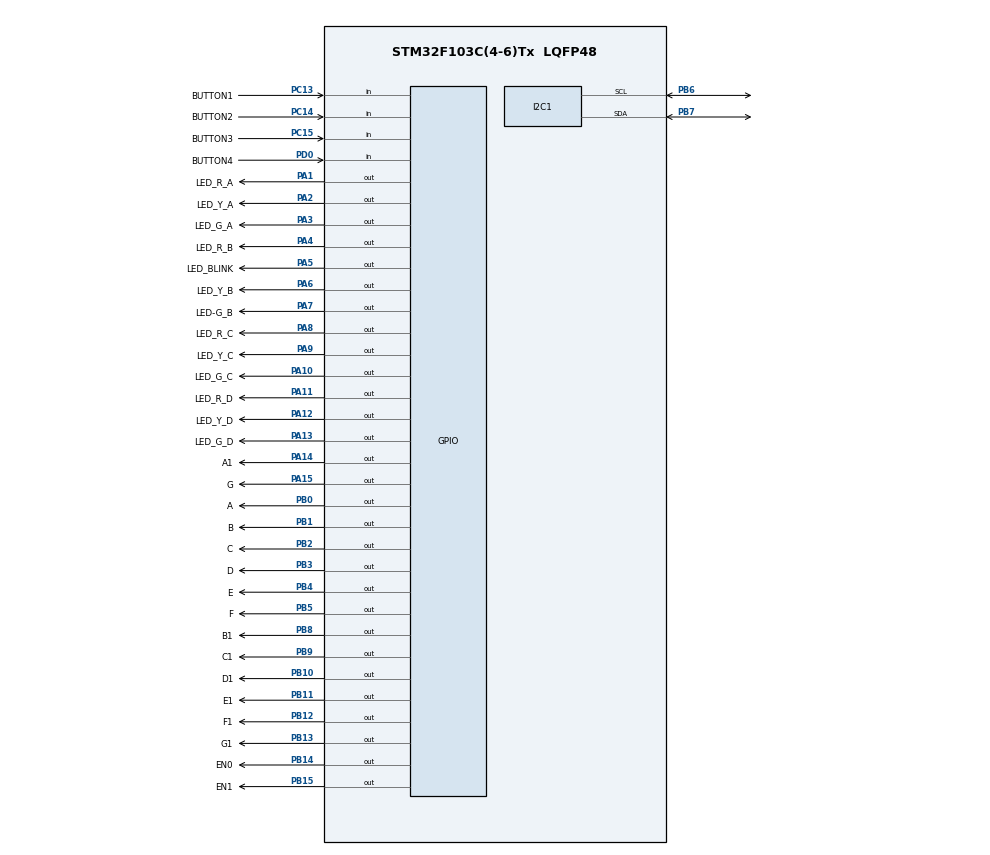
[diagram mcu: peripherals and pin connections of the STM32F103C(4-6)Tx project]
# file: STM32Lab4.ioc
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Mcu.Family=STM32F1
Mcu.Name=STM32F103C(4-6)Tx
Mcu.Package=LQFP48
NVIC.PriorityGroup=NVIC_PRIORITYGROUP_4
NVIC.TIM2_IRQn=true\:0\:0\:false\:false\:true\:true\:true\:true
PA1.GPIO_Label=LED_R_A
PA1.Signal=GPIO_Output
PA10.GPIO_Label=LED_G_C
PA10.Signal=GPIO_Output
PA11.GPIO_Label=LED_R_D
PA11.Signal=GPIO_Output
PA12.GPIO_Label=LED_Y_D
PA12.Signal=GPIO_Output
PA13.GPIO_Label=LED_G_D
PA13.Signal=GPIO_Output
PA14.GPIO_Label=A1
PA14.Signal=GPIO_Output
PA15.GPIO_Label=G
PA15.Signal=GPIO_Output
PA2.GPIO_Label=LED_Y_A
PA2.Signal=GPIO_Output
PA3.GPIO_Label=LED_G_A
PA3.Signal=GPIO_Output
PA4.GPIO_Label=LED_R_B
PA4.Signal=GPIO_Output
PA5.GPIO_Label=LED_BLINK
PA5.Signal=GPIO_Output
PA6.GPIO_Label=LED_Y_B
PA6.Signal=GPIO_Output
PA7.GPIO_Label=LED-G_B
PA7.Signal=GPIO_Output
PA8.GPIO_Label=LED_R_C
PA8.Signal=GPIO_Output
PA9.GPIO_Label=LED_Y_C
PA9.Signal=GPIO_Output
PB0.GPIO_Label=A
PB0.Signal=GPIO_Output
PB1.GPIO_Label=B
PB1.Signal=GPIO_Output
PB10.GPIO_Label=D1
PB10.Signal=GPIO_Output
PB11.GPIO_Label=E1
PB11.Signal=GPIO_Output
PB12.GPIO_Label=F1
PB12.Signal=GPIO_Output
PB13.GPIO_Label=G1
PB13.Signal=GPIO_Output
PB14.GPIO_Label=EN0
PB14.Signal=GPIO_Output
PB15.GPIO_Label=EN1
PB15.Signal=GPIO_Output
PB2.GPIO_Label=C
PB2.Signal=GPIO_Output
PB3.GPIO_Label=D
PB3.Signal=GPIO_Output
PB4.GPIO_Label=E
PB4.Signal=GPIO_Output
PB5.GPIO_Label=F
PB5.Signal=GPIO_Output
PB6.Mode=I2C
PB6.Signal=I2C1_SCL
PB7.Mode=I2C
PB7.Signal=I2C1_SDA
PB8.GPIO_Label=B1
PB8.Signal=GPIO_Output
PB9.GPIO_Label=C1
PB9.Signal=GPIO_Output
PC13-TAMPER-RTC.GPIO_Label=BUTTON1
PC13-TAMPER-RTC.GPIO_PuPd=GPIO_PULLUP
PC13-TAMPER-RTC.Signal=GPIO_Input
PC14-OSC32_IN.GPIO_Label=BUTTON2
PC14-OSC32_IN.GPIO_PuPd=GPIO_PULLUP
PC14-OSC32_IN.Signal=GPIO_Input
PC15-OSC32_OUT.GPIO_Label=BUTTON3
PC15-OSC32_OUT.GPIO_PuPd=GPIO_PULLUP
PC15-OSC32_OUT.Signal=GPIO_Input
PD0-OSC_IN.GPIO_Label=BUTTON4
PD0-OSC_IN.Signal=GPIO_Input
ProjectManager.HeapSize=0x200
ProjectManager.StackSize=0x400
ProjectManager.TargetToolchain=STM32CubeIDE
RCC.APB1Freq_Value=8000000
RCC.APB2Freq_Value=8000000
TIM2.Period=9
TIM2.Prescaler=7999
VP_SYS_VS_ND.Mode=No_Debug
VP_TIM2_VS_ClockSourceINT.Mode=Internal
board=custom

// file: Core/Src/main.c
/* USER CODE BEGIN Header */
/**
  ******************************************************************************
  * @file           : main.c
  * @brief          : Main program body
  ******************************************************************************
  * @attention
  *
  * <h2><center>&copy; Copyright (c) 2025 STMicroelectronics.
  * All rights reserved.</center></h2>
  *
  * This software component is licensed by ST under BSD 3-Clause license,
  * the "License"; You may not use this file except in compliance with the
  * License. You may obtain a copy of the License at:
  *                        opensource.org/licenses/BSD-3-Clause
  *
  ******************************************************************************
  */
/* USER CODE END Header */
#include "main.h"

/* USER CODE BEGIN Includes */
#include "Task.h"

/* USER CODE END Includes */

I2C_HandleTypeDef hi2c1;

TIM_HandleTypeDef htim2;

void SystemClock_Config(void);
static void MX_GPIO_Init(void);
static void MX_TIM2_Init(void);
static void MX_I2C1_Init(void);

int main(void)
{

  /* MCU Configuration--------------------------------------------------------*/

  /* Reset of all peripherals, Initializes the Flash interface and the Systick. */
  HAL_Init();

  /* Configure the system clock */
  SystemClock_Config();

  /* Initialize all configured peripherals */
  MX_GPIO_Init();
  MX_TIM2_Init();
  MX_I2C1_Init();
  /* USER CODE BEGIN 2 */
  doInit();
  SCH_Init();
  SCH_Add_Task(fsm_run_all, 0, 1);
  SCH_Add_Task(BlinkLed, 0, 1);
  HAL_TIM_Base_Start_IT(&htim2);
  /* USER CODE END 2 */

  /* Infinite loop */
  while (1)
  {

    /* USER CODE BEGIN 3 */
	  SCH_Dispatch_Tasks();
  }
  /* USER CODE END 3 */
}

void SystemClock_Config(void)
{
  RCC_OscInitTypeDef RCC_OscInitStruct = {0};
  RCC_ClkInitTypeDef RCC_ClkInitStruct = {0};

  /** Initializes the RCC Oscillators according to the specified parameters
  * in the RCC_OscInitTypeDef structure.
  */
  RCC_OscInitStruct.OscillatorType = RCC_OSCILLATORTYPE_HSI;
  RCC_OscInitStruct.HSIState = RCC_HSI_ON;
  RCC_OscInitStruct.HSICalibrationValue = RCC_HSICALIBRATION_DEFAULT;
  RCC_OscInitStruct.PLL.PLLState = RCC_PLL_NONE;
  if (HAL_RCC_OscConfig(&RCC_OscInitStruct) != HAL_OK)
  {
    Error_Handler();
  }
  /** Initializes the CPU, AHB and APB buses clocks
  */
  RCC_ClkInitStruct.ClockType = RCC_CLOCKTYPE_HCLK|RCC_CLOCKTYPE_SYSCLK
                              |RCC_CLOCKTYPE_PCLK1|RCC_CLOCKTYPE_PCLK2;
  RCC_ClkInitStruct.SYSCLKSource = RCC_SYSCLKSOURCE_HSI;
  RCC_ClkInitStruct.AHBCLKDivider = RCC_SYSCLK_DIV1;
  RCC_ClkInitStruct.APB1CLKDivider = RCC_HCLK_DIV1;
  RCC_ClkInitStruct.APB2CLKDivider = RCC_HCLK_DIV1;

  if (HAL_RCC_ClockConfig(&RCC_ClkInitStruct, FLASH_LATENCY_0) != HAL_OK)
  {
    Error_Handler();
  }
}

static void MX_I2C1_Init(void)
{

  hi2c1.Instance = I2C1;
  hi2c1.Init.ClockSpeed = 100000;
  hi2c1.Init.DutyCycle = I2C_DUTYCYCLE_2;
  hi2c1.Init.OwnAddress1 = 0;
  hi2c1.Init.AddressingMode = I2C_ADDRESSINGMODE_7BIT;
  hi2c1.Init.DualAddressMode = I2C_DUALADDRESS_DISABLE;
  hi2c1.Init.OwnAddress2 = 0;
  hi2c1.Init.GeneralCallMode = I2C_GENERALCALL_DISABLE;
  hi2c1.Init.NoStretchMode = I2C_NOSTRETCH_DISABLE;
  if (HAL_I2C_Init(&hi2c1) != HAL_OK)
  {
    Error_Handler();
  }

}

static void MX_TIM2_Init(void)
{

  TIM_ClockConfigTypeDef sClockSourceConfig = {0};
  TIM_MasterConfigTypeDef sMasterConfig = {0};

  htim2.Instance = TIM2;
  htim2.Init.Prescaler = 7999;
  htim2.Init.CounterMode = TIM_COUNTERMODE_UP;
  htim2.Init.Period = 9;
  htim2.Init.ClockDivision = TIM_CLOCKDIVISION_DIV1;
  htim2.Init.AutoReloadPreload = TIM_AUTORELOAD_PRELOAD_DISABLE;
  if (HAL_TIM_Base_Init(&htim2) != HAL_OK)
  {
    Error_Handler();
  }
  sClockSourceConfig.ClockSource = TIM_CLOCKSOURCE_INTERNAL;
  if (HAL_TIM_ConfigClockSource(&htim2, &sClockSourceConfig) != HAL_OK)
  {
    Error_Handler();
  }
  sMasterConfig.MasterOutputTrigger = TIM_TRGO_RESET;
  sMasterConfig.MasterSlaveMode = TIM_MASTERSLAVEMODE_DISABLE;
  if (HAL_TIMEx_MasterConfigSynchronization(&htim2, &sMasterConfig) != HAL_OK)
  {
    Error_Handler();
  }

}

static void MX_GPIO_Init(void)
{
  GPIO_InitTypeDef GPIO_InitStruct = {0};

  /* GPIO Ports Clock Enable */
  __HAL_RCC_GPIOC_CLK_ENABLE();
  __HAL_RCC_GPIOD_CLK_ENABLE();
  __HAL_RCC_GPIOA_CLK_ENABLE();
  __HAL_RCC_GPIOB_CLK_ENABLE();

  /*Configure GPIO pin Output Level */
  HAL_GPIO_WritePin(GPIOA, LED_R_A_Pin|LED_Y_A_Pin|LED_G_A_Pin|LED_R_B_Pin
                          |LED_BLINK_Pin|LED_Y_B_Pin|LED_G_B_Pin|LED_R_C_Pin
                          |LED_Y_C_Pin|LED_G_C_Pin|LED_R_D_Pin|LED_Y_D_Pin
                          |LED_G_D_Pin|A1_Pin|G_Pin, GPIO_PIN_RESET);

  /*Configure GPIO pin Output Level */
  HAL_GPIO_WritePin(GPIOB, A_Pin|B_Pin|C_Pin|D1_Pin
                          |E1_Pin|F1_Pin|G1_Pin|EN0_Pin
                          |EN1_Pin|D_Pin|E_Pin|F_Pin
                          |B1_Pin|C1_Pin, GPIO_PIN_RESET);

  /*Configure GPIO pins : BUTTON1_Pin BUTTON2_Pin BUTTON3_Pin */
  GPIO_InitStruct.Pin = BUTTON1_Pin|BUTTON2_Pin|BUTTON3_Pin;
  GPIO_InitStruct.Mode = GPIO_MODE_INPUT;
  GPIO_InitStruct.Pull = GPIO_PULLUP;
  HAL_GPIO_Init(GPIOC, &GPIO_InitStruct);

  /*Configure GPIO pin : BUTTON4_Pin */
  GPIO_InitStruct.Pin = BUTTON4_Pin;
  GPIO_InitStruct.Mode = GPIO_MODE_INPUT;
  GPIO_InitStruct.Pull = GPIO_NOPULL;
  HAL_GPIO_Init(BUTTON4_GPIO_Port, &GPIO_InitStruct);

  /*Configure GPIO pins : LED_R_A_Pin LED_Y_A_Pin LED_G_A_Pin LED_R_B_Pin
                           LED_BLINK_Pin LED_Y_B_Pin LED_G_B_Pin LED_R_C_Pin
                           LED_Y_C_Pin LED_G_C_Pin LED_R_D_Pin LED_Y_D_Pin
                           LED_G_D_Pin A1_Pin G_Pin */
  GPIO_InitStruct.Pin = LED_R_A_Pin|LED_Y_A_Pin|LED_G_A_Pin|LED_R_B_Pin
                          |LED_BLINK_Pin|LED_Y_B_Pin|LED_G_B_Pin|LED_R_C_Pin
                          |LED_Y_C_Pin|LED_G_C_Pin|LED_R_D_Pin|LED_Y_D_Pin
                          |LED_G_D_Pin|A1_Pin|G_Pin;
  GPIO_InitStruct.Mode = GPIO_MODE_OUTPUT_PP;
  GPIO_InitStruct.Pull = GPIO_NOPULL;
  GPIO_InitStruct.Speed = GPIO_SPEED_FREQ_LOW;
  HAL_GPIO_Init(GPIOA, &GPIO_InitStruct);

  /*Configure GPIO pins : A_Pin B_Pin C_Pin D1_Pin
                           E1_Pin F1_Pin G1_Pin EN0_Pin
                           EN1_Pin D_Pin E_Pin F_Pin
                           B1_Pin C1_Pin */
  GPIO_InitStruct.Pin = A_Pin|B_Pin|C_Pin|D1_Pin
                          |E1_Pin|F1_Pin|G1_Pin|EN0_Pin
                          |EN1_Pin|D_Pin|E_Pin|F_Pin
                          |B1_Pin|C1_Pin;
  GPIO_InitStruct.Mode = GPIO_MODE_OUTPUT_PP;
  GPIO_InitStruct.Pull = GPIO_NOPULL;
  GPIO_InitStruct.Speed = GPIO_SPEED_FREQ_LOW;
  HAL_GPIO_Init(GPIOB, &GPIO_InitStruct);

  /*Configure peripheral I/O remapping */
  __HAL_AFIO_REMAP_PD01_ENABLE();

}

/* USER CODE BEGIN 4 */
void HAL_TIM_PeriodElapsedCallback(TIM_HandleTypeDef *htim){
	SCH_TimerCallback();
	timer_run();
	getKeyInput();
	button_event_scan();
}
/* USER CODE END 4 */

void Error_Handler(void)
{
  __disable_irq();
  while (1)
  {
  }
}

/************************ (C) COPYRIGHT STMicroelectronics *****END OF FILE****/
